# LPC112x register map
File version: 0.3
CPU: CM0 r0p0, little endian, no MPU, no FPU, 2 interrupt priority bits
Registers are 32-bit, read-write, reset 0x0 unless marked. A register's access mark holds for its fields unless they carry their own. Offsets are from the block's base; [hi:lo] are bit positions; 'fields as' and 'values as' point back to an identical list.

## IOCON — I/O configuration (IOCON)
Base 0x40044000
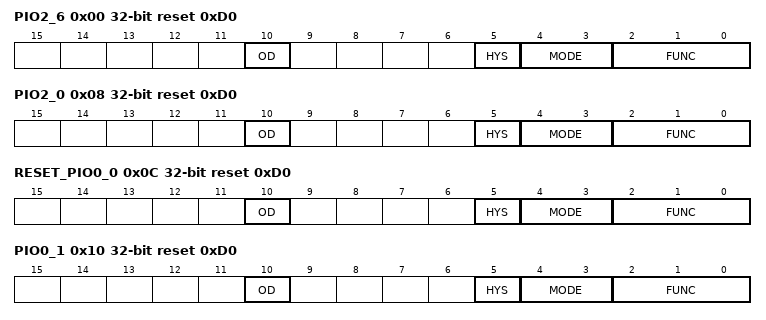
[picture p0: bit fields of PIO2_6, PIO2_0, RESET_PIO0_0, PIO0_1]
0x00 PIO2_6 reset 0xD0 — I/O configuration for pin PIO2_6/ CT32B0_MAT1
  [10] OD — Selects pseudo open-drain mode.
    0=STANDARD_GPIO_OUTPUT; 1=OPEN_DRAIN_OUTPUT
  [5] HYS — Hysteresis.
    0=DISABLE; 1=ENABLE
  [4:3] MODE — Selects function mode (on-chip pull-up/pull-down resistor control).
    0=INACTIVE_NO_PULL_DO (Inactive (no pull-down/pull-up resistor enabled).); 1=PULL_DOWN_RESISTOR_E (Pull-down resistor enabled.); 2=PULL_UP_RESISTOR_ENA (Pull-up resistor enabled.); 3=REPEATER_MODE
  [2:0] FUNC — Selects pin function. All other values are reserved.
    0=PIO2_6; 1=CT32B0_MAT1
0x08 PIO2_0 reset 0xD0 — I/O configuration for pin PIO2_0/U0_DTR/SSP1_SSEL/ ADC_PIN_TRIG4
  [10] OD — Selects pseudo open-drain mode.
    0=STANDARD_GPIO_OUTPUT; 1=OPEN_DRAIN_OUTPUT
  [5] HYS — Hysteresis.
    0=DISABLE; 1=ENABLE
  [4:3] MODE — Selects function mode (on-chip pull-up/pull-down resistor control).
    values as PIO2_6.MODE
  [2:0] FUNC — Selects pin function. All other values are reserved.
    0=PIO2_0; 1=U0_DTR; 2=SSP1_SSEL; 3=ADC_PIN_TRIG4
0x0C RESET_PIO0_0 reset 0xD0 — I/O configuration for pin RESET/PIO0_0
  [10] OD — Selects pseudo open-drain mode.
    0=STANDARD_GPIO_OUTPUT; 1=OPEN_DRAIN_OUTPUT
  [5] HYS — Hysteresis.
    0=DISABLE; 1=ENABLE
  [4:3] MODE — Selects function mode (on-chip pull-up/pull-down resistor control).
    values as PIO2_6.MODE
  [2:0] FUNC — Selects pin function. All other values are reserved.
    0=RESET; 1=PIO0_0
0x10 PIO0_1 reset 0xD0 — I/O configuration for pin PIO0_1/CLKOUT/CT32B0_MAT2
  [10] OD — Selects pseudo open-drain mode.
    0=STANDARD_GPIO_OUTPUT; 1=OPEN_DRAIN_OUTPUT
  [5] HYS — Hysteresis.
    0=DISABLE; 1=ENABLE
  [4:3] MODE — Selects function mode (on-chip pull-up/pull-down resistor control).
    values as PIO2_6.MODE
  [2:0] FUNC — Selects pin function. All other values are reserved.
    0=PIO0_1; 1=CLKOUT; 2=CT32B0_MAT2
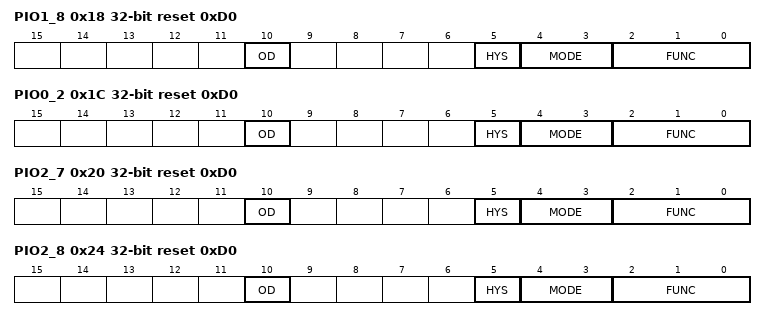
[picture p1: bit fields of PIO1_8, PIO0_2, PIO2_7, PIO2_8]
0x18 PIO1_8 reset 0xD0 — I/O configuration for pin PIO1_8/CT16B1_CAP0/R/U2_TXD
  [10] OD — Selects pseudo open-drain mode.
    0=STANDARD_GPIO_OUTPUT; 1=OPEN_DRAIN_OUTPUT
  [5] HYS — Hysteresis.
    0=DISABLE; 1=ENABLE
  [4:3] MODE — Selects function mode (on-chip pull-up/pull-down resistor control).
    values as PIO2_6.MODE
  [2:0] FUNC — Selects pin function. All other values are reserved.
    0=PIO1_8; 1=CT16B1_CAP0; 3=U2_TXD
0x1C PIO0_2 reset 0xD0 — I/O configuration for pin PIO0_2/SSP0_SSEL/CT16B0_CAP0/ ADC_PIN_TRIG0
  [10] OD — Selects pseudo open-drain mode.
    0=STANDARD_GPIO_OUTPUT; 1=OPEN_DRAIN_OUTPUT
  [5] HYS — Hysteresis.
    0=DISABLE; 1=ENABLE
  [4:3] MODE — Selects function mode (on-chip pull-up/pull-down resistor control).
    values as PIO2_6.MODE
  [2:0] FUNC — Selects pin function. All other values are reserved.
    0=PIO0_2; 1=SSP0_SSEL; 2=CT16B0_CAP0; 3=ADC_PIN_TRIG0
0x20 PIO2_7 reset 0xD0 — I/O configuration for pin PIO2_7/ CT32B0_MAT2/U0_RXD
  [10] OD — Selects pseudo open-drain mode.
    0=STANDARD_GPIO_OUTPUT; 1=OPEN_DRAIN_OUTPUT
  [5] HYS — Hysteresis.
    0=DISABLE; 1=ENABLE
  [4:3] MODE — Selects function mode (on-chip pull-up/pull-down resistor control).
    values as PIO2_6.MODE
  [2:0] FUNC — Selects pin function. All other values are reserved.
    0=PIO2_7; 1=CT32B0_MAT2; 2=U0_RXD
0x24 PIO2_8 reset 0xD0 — I/O configuration for pin PIO2_8/ CT32B0_MAT3/U0_TXD
  [10] OD — Selects pseudo open-drain mode.
    0=STANDARD_GPIO_OUTPUT; 1=OPEN_DRAIN_OUTPUT
  [5] HYS — Hysteresis.
    0=DISABLE; 1=ENABLE
  [4:3] MODE — Selects function mode (on-chip pull-up/pull-down resistor control).
    values as PIO2_6.MODE
  [2:0] FUNC — Selects pin function. All other values are reserved.
    0=PIO2_8; 1=CT32B0_MAT3; 2=U0_TXD
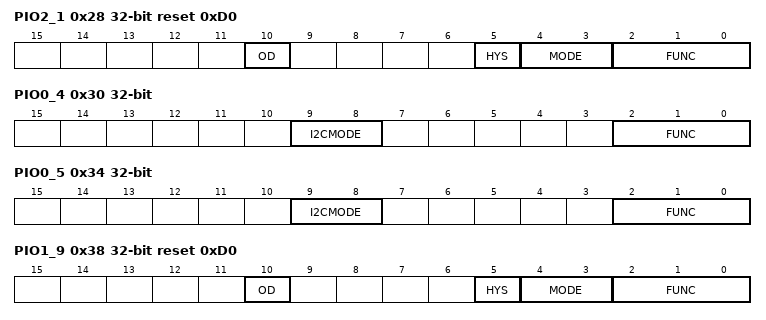
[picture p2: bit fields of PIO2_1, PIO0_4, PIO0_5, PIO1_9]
0x28 PIO2_1 reset 0xD0 — I/O configuration for pin PIO2_1/U0_DSR/SSP1_SCK
  [10] OD — Selects pseudo open-drain mode.
    0=STANDARD_GPIO_OUTPUT; 1=OPEN_DRAIN_OUTPUT
  [5] HYS — Hysteresis.
    0=DISABLE; 1=ENABLE
  [4:3] MODE — Selects function mode (on-chip pull-up/pull-down resistor control).
    values as PIO2_6.MODE
  [2:0] FUNC — Selects pin function. All other values are reserved.
    0=PIO2_1; 1=U0_DSR; 2=SSP1_SCK
0x30 PIO0_4 — I/O configuration for pin PIO0_4/I2C0_SCL
  [9:8] I2CMODE — Selects I2C mode. Select Standard mode (I2CMODE = 00, default) or Standard I/O functionality (I2CMODE = 01) if the pin function is GPIO (FUNC = 000).
    0=STANDARD_FAST (Standard mode/ Fast-mode I2C.); 1=STANDARDIO (Standard I/O functionality); 2=FAST_MODE_PLUS_I2C
  [2:0] FUNC — Selects pin function. All other values are reserved.
    0=PIO0_4_OPEN_DRAIN_P (PIO0_4 (open-drain pin).); 1=I2C0_SCL_OPEN_DRAIN (I2C0_SCL (open-drain pin).)
0x34 PIO0_5 — I/O configuration for pin PIO0_5/I2C0_SDA
  [9:8] I2CMODE — Selects I2C mode. Select Standard mode (I2CMODE = 00, default) or Standard I/O functionality (I2CMODE = 01) if the pin function is GPIO (FUNC = 000).
    values as PIO0_4.I2CMODE
  [2:0] FUNC — Selects pin function. All other values are reserved.
    0=PIO0_5_OPEN_DRAIN_P (PIO0_5 (open-drain pin).); 1=I2C0_SDA_OPEN_DRAIN (I2C0_SDA (open-drain pin).)
0x38 PIO1_9 reset 0xD0 — I/O configuration for pin PIO1_9/CT16B1_MAT0/SSP1_ MOSI
  [10] OD — Selects pseudo open-drain mode.
    0=STANDARD_GPIO_OUTPUT; 1=OPEN_DRAIN_OUTPUT
  [5] HYS — Hysteresis.
    0=DISABLE; 1=ENABLE
  [4:3] MODE — Selects function mode (on-chip pull-up/pull-down resistor control).
    values as PIO2_6.MODE
  [2:0] FUNC — Selects pin function. All other values are reserved.
    0=PIO1_9; 1=CT16B1_MAT0; 2=SSP1_MOSI
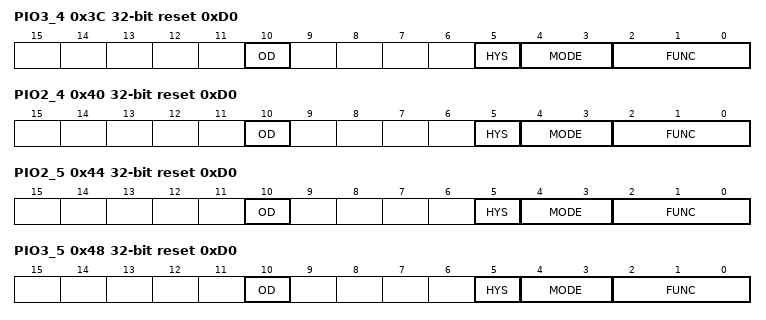
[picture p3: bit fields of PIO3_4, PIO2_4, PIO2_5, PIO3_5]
0x3C PIO3_4 reset 0xD0 — I/O configuration for pin PIO3_4/ CT16B0_CAP1/U0_RXD
  [10] OD — Selects pseudo open-drain mode.
    0=STANDARD_GPIO_OUTPUT; 1=OPEN_DRAIN_OUTPUT
  [5] HYS — Hysteresis.
    0=DISABLE; 1=ENABLE
  [4:3] MODE — Selects function mode (on-chip pull-up/pull-down resistor control).
    values as PIO2_6.MODE
  [2:0] FUNC — Selects pin function. All other values are reserved.
    0=PIO3_4; 1=CT16B0_CAP1; 2=U0_RXD
0x40 PIO2_4 reset 0xD0 — I/O configuration for pin PIO2_4/ CT16B1_MAT1/ SSP1_SSEL
  [10] OD — Selects pseudo open-drain mode.
    0=STANDARD_GPIO_OUTPUT; 1=OPEN_DRAIN_OUTPUT
  [5] HYS — Hysteresis.
    0=DISABLE; 1=ENABLE
  [4:3] MODE — Selects function mode (on-chip pull-up/pull-down resistor control).
    values as PIO2_6.MODE
  [2:0] FUNC — Selects pin function. All other values are reserved.
    0=PIO2_4; 1=CT16B1_MAT1; 2=SSP1_SSEL
0x44 PIO2_5 reset 0xD0 — I/O configuration for pin PIO2_5/ CT32B0_MAT0
  [10] OD — Selects pseudo open-drain mode.
    0=STANDARD_GPIO_OUTPUT; 1=OPEN_DRAIN_OUTPUT
  [5] HYS — Hysteresis.
    0=DISABLE; 1=ENABLE
  [4:3] MODE — Selects function mode (on-chip pull-up/pull-down resistor control).
    values as PIO2_6.MODE
  [2:0] FUNC — Selects pin function. All other values are reserved.
    0=PIO2_5; 1=CT32B0_MAT0
0x48 PIO3_5 reset 0xD0 — I/O configuration for pin PIO3_5/ CT16B1_CAP1/U0_TXD
  [10] OD — Selects pseudo open-drain mode.
    0=STANDARD_GPIO_OUTPUT; 1=OPEN_DRAIN_OUTPUT
  [5] HYS — Hysteresis.
    0=DISABLE; 1=ENABLE
  [4:3] MODE — Selects function mode (on-chip pull-up/pull-down resistor control).
    values as PIO2_6.MODE
  [2:0] FUNC — Selects pin function. All other values are reserved.
    0=PIO3_5; 1=CT16B1_CAP1; 2=U0_TXD
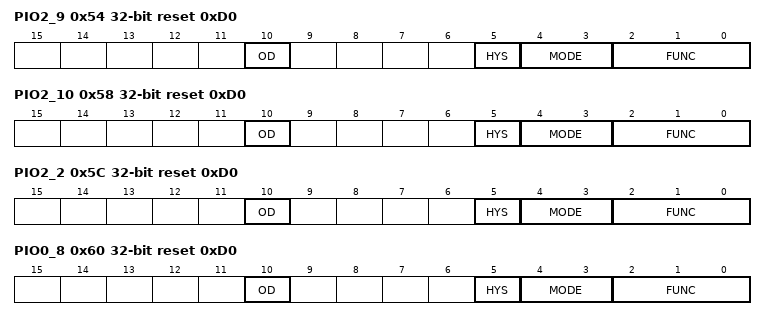
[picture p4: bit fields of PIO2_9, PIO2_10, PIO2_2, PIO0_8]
0x54 PIO2_9 reset 0xD0 — I/O configuration for pin PIO2_9/ CT32B0_CAP0
  [10] OD — Selects pseudo open-drain mode.
    0=STANDARD_GPIO_OUTPUT; 1=OPEN_DRAIN_OUTPUT
  [5] HYS — Hysteresis.
    0=DISABLE; 1=ENABLE
  [4:3] MODE — Selects function mode (on-chip pull-up/pull-down resistor control).
    values as PIO2_6.MODE
  [2:0] FUNC — Selects pin function. All other values are reserved.
    0=PIO2_9; 1=CT32B0_CAP0
0x58 PIO2_10 reset 0xD0 — I/O configuration for pin PIO2_10
  [10] OD — Selects pseudo open-drain mode.
    0=STANDARD_GPIO_OUTPUT; 1=OPEN_DRAIN_OUTPUT
  [5] HYS — Hysteresis.
    0=DISABLE; 1=ENABLE
  [4:3] MODE — Selects function mode (on-chip pull-up/pull-down resistor control).
    values as PIO2_6.MODE
  [2:0] FUNC — Selects pin function. All other values are reserved.
    0=PIO2_10
0x5C PIO2_2 reset 0xD0 — I/O configuration for pin PIO2_2/U0_DCD/SSP1_MISO
  [10] OD — Selects pseudo open-drain mode.
    0=STANDARD_GPIO_OUTPUT; 1=OPEN_DRAIN_OUTPUT
  [5] HYS — Hysteresis.
    0=DISABLE; 1=ENABLE
  [4:3] MODE — Selects function mode (on-chip pull-up/pull-down resistor control).
    values as PIO2_6.MODE
  [2:0] FUNC — Selects pin function. All other values are reserved.
    0=PIO2_2; 1=U0_DCD; 2=SSP1_MISO
0x60 PIO0_8 reset 0xD0 — I/O configuration for pin PIO0_8/SSP0_MISO/CT16B0_MAT0/R/ADC_PIN_TRIG2
  [10] OD — Selects pseudo open-drain mode.
    0=STANDARD_GPIO_OUTPUT; 1=OPEN_DRAIN_OUTPUT
  [5] HYS — Hysteresis.
    0=DISABLE; 1=ENABLE
  [4:3] MODE — Selects function mode (on-chip pull-up/pull-down resistor control).
    values as PIO2_6.MODE
  [2:0] FUNC — Selects pin function. All other values are reserved.
    0=PIO0_8; 1=SSP0_MISO; 2=CT16B0_MAT0; 4=ADC_PIN_TRIG2
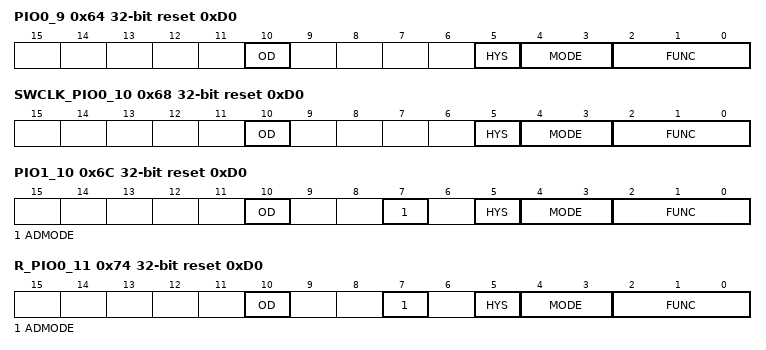
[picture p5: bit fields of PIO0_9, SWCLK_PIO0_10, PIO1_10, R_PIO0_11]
0x64 PIO0_9 reset 0xD0 — I/O configuration for pin PIO0_9SSP0_MOSI/CT16B0_MAT1/R/ADC_PIN_TRIG3
  [10] OD — Selects pseudo open-drain mode.
    0=STANDARD_GPIO_OUTPUT; 1=OPEN_DRAIN_OUTPUT
  [5] HYS — Hysteresis.
    0=DISABLE; 1=ENABLE
  [4:3] MODE — Selects function mode (on-chip pull-up/pull-down resistor control).
    values as PIO2_6.MODE
  [2:0] FUNC — Selects pin function. All other values are reserved.
    0=PIO0_9; 1=SSP0_MOSI; 2=CT16B0_MAT1; 4=ADC_PIN_TRIG3
0x68 SWCLK_PIO0_10 reset 0xD0 — I/O configuration for pin SWCLK/PIO0_10/ SSP0_SCK/CT16B0_MAT2
  [10] OD — Selects pseudo open-drain mode.
    0=STANDARD_GPIO_OUTPUT; 1=OPEN_DRAIN_OUTPUT
  [5] HYS — Hysteresis.
    0=DISABLE; 1=ENABLE
  [4:3] MODE — Selects function mode (on-chip pull-up/pull-down resistor control).
    values as PIO2_6.MODE
  [2:0] FUNC — Selects pin function. All other values are reserved.
    0=SWCLK; 1=PIO0_10; 2=SSP0_SCK_ONLY_IF_PI (SSP0_SCK (only if pin SWCLK/PIO0_10/SSP0_SCK/CT16B0_MAT2 selected in the SCK0_LOC register).); 3=CT16B0_MAT2
0x6C PIO1_10 reset 0xD0 — I/O configuration for pin PIO1_10/ADC_8/CT16B1_MAT1/ SSP1_MISO
  [10] OD — Selects pseudo open-drain mode.
    0=STANDARD_GPIO_OUTPUT; 1=OPEN_DRAIN_OUTPUT
  [7] ADMODE — Selects Analog/Digital mode
    0=ANALOG_INPUT_MODE; 1=DIGITAL_FUNCTIONAL_M (Digital functional mode)
  [5] HYS — Hysteresis.
    0=DISABLE; 1=ENABLE
  [4:3] MODE — Selects function mode (on-chip pull-up/pull-down resistor control).
    values as PIO2_6.MODE
  [2:0] FUNC — Selects pin function. All other values are reserved.
    0=PIO1_10; 1=ADC_8; 2=CT16B1_MAT1; 3=SSP1_MISO
0x74 R_PIO0_11 reset 0xD0 — I/O configuration for pin R/PIO0_11/ADC_7/CT32B0_MAT3
  [10] OD — Selects pseudo open-drain mode.
    0=STANDARD_GPIO_OUTPUT; 1=OPEN_DRAIN_OUTPUT
  [7] ADMODE — Selects Analog/Digital mode
    values as PIO1_10.ADMODE
  [5] HYS — Hysteresis.
    0=DISABLE; 1=ENABLE
  [4:3] MODE — Selects function mode (on-chip pull-up/pull-down resistor control).
    values as PIO2_6.MODE
  [2:0] FUNC — Selects pin function. All other values are reserved.
    0=R (R. This function is reserved. Select one of the alternate functions below.); 1=PIO0_11; 2=ADC_7; 3=CT32B0_MAT3
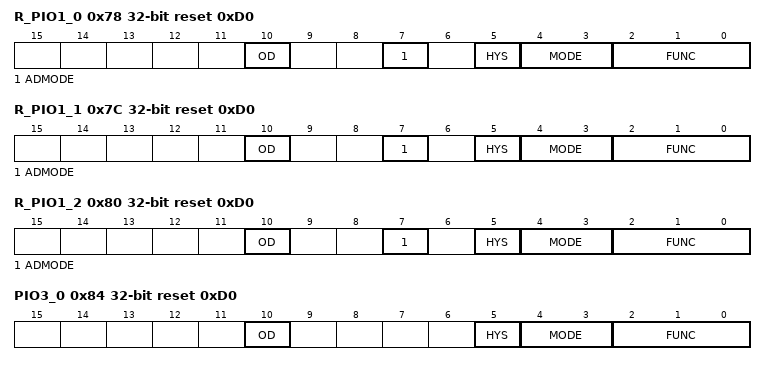
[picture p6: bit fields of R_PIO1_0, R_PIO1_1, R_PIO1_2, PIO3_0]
0x78 R_PIO1_0 reset 0xD0 — I/O configuration for pin R/PIO1_0/ADC_6/CT32B1_CAP0
  [10] OD — Selects pseudo open-drain mode.
    0=STANDARD_GPIO_OUTPUT; 1=OPEN_DRAIN_OUTPUT
  [7] ADMODE — Selects Analog/Digital mode
    values as PIO1_10.ADMODE
  [5] HYS — Hysteresis.
    0=DISABLE; 1=ENABLE
  [4:3] MODE — Selects function mode (on-chip pull-up/pull-down resistor control).
    values as PIO2_6.MODE
  [2:0] FUNC — Selects pin function. All other values are reserved.
    0=R (R. This function is reserved. Select one of the alternate functions below.); 1=PIO1_0; 2=ADC_6; 3=CT32B1_CAP0
0x7C R_PIO1_1 reset 0xD0 — I/O configuration for pin R/PIO1_1/ADC_5/CT32B1_MAT0
  [10] OD — Selects pseudo open-drain mode.
    0=STANDARD_GPIO_OUTPUT; 1=OPEN_DRAIN_OUTPUT
  [7] ADMODE — Selects Analog/Digital mode
    values as PIO1_10.ADMODE
  [5] HYS — Hysteresis.
    0=DISABLE; 1=ENABLE
  [4:3] MODE — Selects function mode (on-chip pull-up/pull-down resistor control).
    values as PIO2_6.MODE
  [2:0] FUNC — Selects pin function. All other values are reserved.
    0=R (R. This function is reserved. Select one of the alternate functions below.); 1=PIO1_1; 2=ADC_5; 3=CT32B1_MAT0
0x80 R_PIO1_2 reset 0xD0 — I/O configuration for pin R/PIO1_2/ADC_4/CT32B1_MAT1
  [10] OD — Selects pseudo open-drain mode.
    0=STANDARD_GPIO_OUTPUT; 1=OPEN_DRAIN_OUTPUT
  [7] ADMODE — Selects Analog/Digital mode
    values as PIO1_10.ADMODE
  [5] HYS — Hysteresis.
    0=DISABLE; 1=ENABLE
  [4:3] MODE — Selects function mode (on-chip pull-up/pull-down resistor control).
    values as PIO2_6.MODE
  [2:0] FUNC — Selects pin function. All other values are reserved.
    0=R (R. This function is reserved. Select one of the alternate functions below.); 1=PIO1_2; 2=ADC_4; 3=CT32B1_MAT1
0x84 PIO3_0 reset 0xD0 — I/O configuration for pin PIO3_0/U0_DTR/CT16B0_MAT0/ U0_TXD
  [10] OD — Selects pseudo open-drain mode.
    0=STANDARD_GPIO_OUTPUT; 1=OPEN_DRAIN_OUTPUT
  [5] HYS — Hysteresis.
    0=DISABLE; 1=ENABLE
  [4:3] MODE — Selects function mode (on-chip pull-up/pull-down resistor control).
    values as PIO2_6.MODE
  [2:0] FUNC — Selects pin function. All other values are reserved.
    0=PIO3_0; 1=U0_DTR; 2=CT16B0_MAT0; 3=U0_TXD
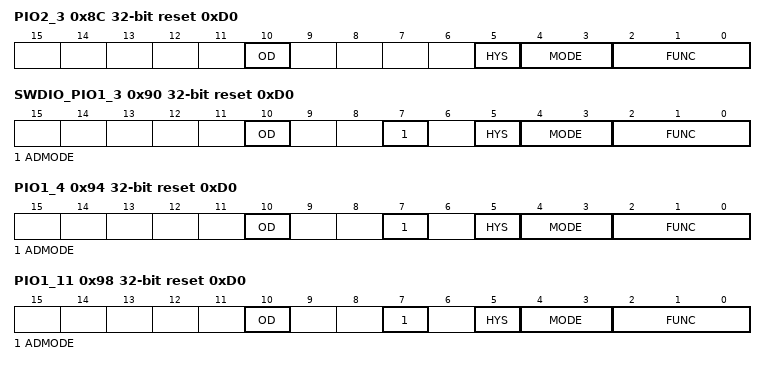
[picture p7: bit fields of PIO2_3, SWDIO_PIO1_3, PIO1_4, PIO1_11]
0x8C PIO2_3 reset 0xD0 — I/O configuration for pin PIO2_3/U0_RI/SSP1_MOSI
  [10] OD — Selects pseudo open-drain mode.
    0=STANDARD_GPIO_OUTPUT; 1=OPEN_DRAIN_OUTPUT
  [5] HYS — Hysteresis.
    0=DISABLE; 1=ENABLE
  [4:3] MODE — Selects function mode (on-chip pull-up/pull-down resistor control).
    values as PIO2_6.MODE
  [2:0] FUNC — Selects pin function. All other values are reserved.
    0=PIO2_3; 1=U0_RI; 2=SSP1_MOSI
0x90 SWDIO_PIO1_3 reset 0xD0 — I/O configuration for pin SWDIO/PIO1_3/ADC_3/CT32B1_MAT2
  [10] OD — Selects pseudo open-drain mode.
    0=STANDARD_GPIO_OUTPUT; 1=OPEN_DRAIN_OUTPUT
  [7] ADMODE — Selects Analog/Digital mode
    values as PIO1_10.ADMODE
  [5] HYS — Hysteresis.
    0=DISABLE; 1=ENABLE
  [4:3] MODE — Selects function mode (on-chip pull-up/pull-down resistor control).
    values as PIO2_6.MODE
  [2:0] FUNC — Selects pin function. All other values are reserved.
    0=SWDIO; 1=PIO1_3; 2=ADC_3; 3=CT32B1_MAT2
0x94 PIO1_4 reset 0xD0 — I/O configuration for pin PIO1_4/ADC_2/CT32B1_MAT3
  [10] OD — Selects pseudo open-drain mode.
    0=STANDARD_GPIO_OUTPUT; 1=OPEN_DRAIN_OUTPUT
  [7] ADMODE — Selects Analog/Digital mode
    values as PIO1_10.ADMODE
  [5] HYS — Hysteresis.
    0=DISABLE; 1=ENABLE
  [4:3] MODE — Selects function mode (on-chip pull-up/pull-down resistor control).
    values as PIO2_6.MODE
  [2:0] FUNC — Selects pin function. This pin functions as WAKEUP pin if the part is in Deep power-down mode regardless of the value of FUNC. All other values are reserved.
    0=PIO1_4; 1=ADC_2; 2=CT32B1_MAT3
0x98 PIO1_11 reset 0xD0 — I/O configuration for pin PIO1_11/ADC_1/CT32B1_CAP1
  [10] OD — Selects pseudo open-drain mode.
    0=STANDARD_GPIO_OUTPUT; 1=OPEN_DRAIN_OUTPUT
  [7] ADMODE — Selects Analog/Digital mode
    values as PIO1_10.ADMODE
  [5] HYS — Hysteresis.
    0=DISABLE; 1=ENABLE
  [4:3] MODE — Selects function mode (on-chip pull-up/pull-down resistor control).
    values as PIO2_6.MODE
  [2:0] FUNC — Selects pin function. All other values are reserved.
    0=PIO1_11; 1=ADC_1; 2=CT32B1_CAP1
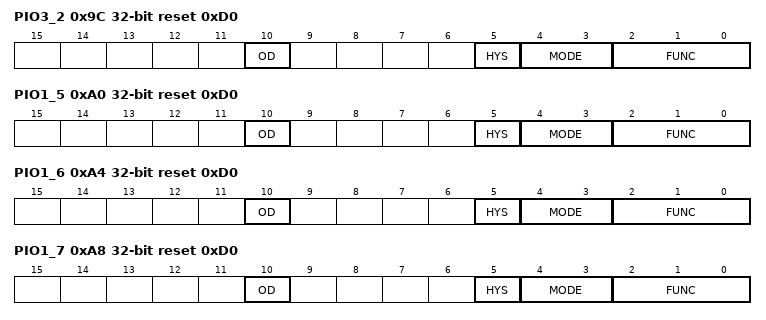
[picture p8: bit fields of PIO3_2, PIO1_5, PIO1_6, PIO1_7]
0x9C PIO3_2 reset 0xD0 — I/O configuration for pin PIO3_2/U0_DCD/ CT16B0_MAT2/SSP1_SCK
  [10] OD — Selects pseudo open-drain mode.
    0=STANDARD_GPIO_OUTPUT; 1=OPEN_DRAIN_OUTPUT
  [5] HYS — Hysteresis.
    0=DISABLE; 1=ENABLE
  [4:3] MODE — Selects function mode (on-chip pull-up/pull-down resistor control).
    values as PIO2_6.MODE
  [2:0] FUNC — Selects pin function. All other values are reserved.
    0=PIO3_2; 1=U0_DCD; 2=CT16B0_MAT2; 3=SSP1_SCK
0xA0 PIO1_5 reset 0xD0 — I/O configuration for pin PIO1_5/U0_RTS/CT32B0_CAP0
  [10] OD — Selects pseudo open-drain mode.
    0=STANDARD_GPIO_OUTPUT; 1=OPEN_DRAIN_OUTPUT
  [5] HYS — Hysteresis.
    0=DISABLE; 1=ENABLE
  [4:3] MODE — Selects function mode (on-chip pull-up/pull-down resistor control).
    values as PIO2_6.MODE
  [2:0] FUNC — Selects pin function. All other values are reserved.
    0=PIO1_5; 1=U0_RTS; 2=CT32B0_CAP0
0xA4 PIO1_6 reset 0xD0 — I/O configuration for pin PIO1_6/U0_RXD/CT32B0_MAT0
  [10] OD — Selects pseudo open-drain mode.
    0=STANDARD_GPIO_OUTPUT; 1=OPEN_DRAIN_OUTPUT
  [5] HYS — Hysteresis.
    0=DISABLE; 1=ENABLE
  [4:3] MODE — Selects function mode (on-chip pull-up/pull-down resistor control).
    values as PIO2_6.MODE
  [2:0] FUNC — Selects pin function. All other values are reserved.
    0=PIO1_6; 1=U0_RXD; 2=CT32B0_MAT0
0xA8 PIO1_7 reset 0xD0 — I/O configuration for pin PIO1_7/U0_TXD/CT32B0_MAT1
  [10] OD — Selects pseudo open-drain mode.
    0=STANDARD_GPIO_OUTPUT; 1=OPEN_DRAIN_OUTPUT
  [5] HYS — Hysteresis.
    0=DISABLE; 1=ENABLE
  [4:3] MODE — Selects function mode (on-chip pull-up/pull-down resistor control).
    values as PIO2_6.MODE
  [2:0] FUNC — Selects pin function. All other values are reserved.
    0=PIO1_7; 1=U0_TXD; 2=CT32B0_MAT1
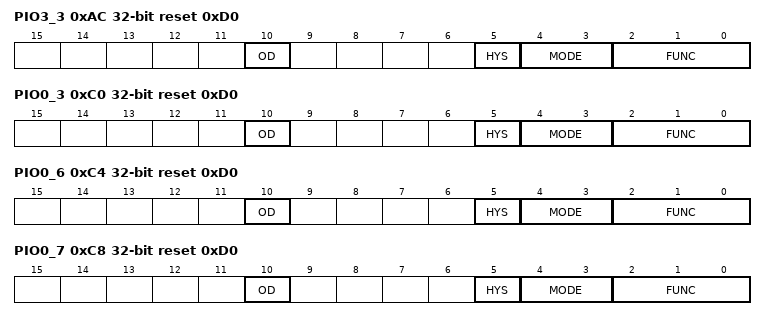
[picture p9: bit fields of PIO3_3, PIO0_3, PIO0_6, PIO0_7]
0xAC PIO3_3 reset 0xD0 — I/O configuration for pin PIO3_3/U0_RI/ CT16B0_CAP0
  [10] OD — Selects pseudo open-drain mode.
    0=STANDARD_GPIO_OUTPUT; 1=OPEN_DRAIN_OUTPUT
  [5] HYS — Hysteresis.
    0=DISABLE; 1=ENABLE
  [4:3] MODE — Selects function mode (on-chip pull-up/pull-down resistor control).
    values as PIO2_6.MODE
  [2:0] FUNC — Selects pin function. All other values are reserved.
    0=PIO3_3; 1=U0_RI; 2=CT16B0_CAP0
0xB0 SCK0_LOC — SCK0 pin location select register
  [1:0] SCKLOC — Selects pin location for SSP0_SCK function.
    0=PIO0_10 (PIO0_10. Selects SCK0 function in pin location SWCLK/PIO0_10.); 2=PIO0_6 (PIO0_6. Selects SSP0_SCK function in pin location PIO0_6.)
0xB4 DSR_LOC — DSR pin location select register
  [1:0] DSRLOC — Selects pin location for U0_DSR function.
    0=PIO2_1 (PIO2_1. Selects U0_DSR function in pin location PIO2_1)
0xB8 DCD_LOC — DCD pin location select register
  [1:0] DCDLOC — Selects pin location for U0_DCD function.
    0=PIO2_2 (PIO2_2. Selects U0_DCD function in pin location PIO2_2.); 1=PIO3_2 (PIO3_2. Selects U0_DCD function in pin location PIO3_2.)
0xBC RI_LOC — RI pin location select register
  [1:0] RILOC — Selects pin location for U0_RI function.
    0=PIO2_3 (PIO2_3. Selects UO_RI function in pin location PIO2_3.); 1=PIO3_3 (PIO3_3. Selects U0_RI function in pin location PIO3_3.)
0xC0 PIO0_3 reset 0xD0 — I/O configuration for pin PIO0_3/R/R/U2_RXD
  [10] OD — Selects pseudo open-drain mode.
    0=STANDARD_GPIO_OUTPUT; 1=OPEN_DRAIN_OUTPUT
  [5] HYS — Hysteresis.
    0=DISABLE; 1=ENABLE
  [4:3] MODE — Selects function mode (on-chip pull-up/pull-down resistor control).
    values as PIO2_6.MODE
  [2:0] FUNC — Selects pin function. All other values are reserved.
    0=PIO0_3; 3=U2_RXD
0xC4 PIO0_6 reset 0xD0 — I/O configuration for pin PIO0_6/SSP0_SCK/U1_TXD
  [10] OD — Selects pseudo open-drain mode.
    0=STANDARD_GPIO_OUTPUT; 1=OPEN_DRAIN_OUTPUT
  [5] HYS — Hysteresis.
    0=DISABLE; 1=ENABLE
  [4:3] MODE — Selects function mode (on-chip pull-up/pull-down resistor control).
    values as PIO2_6.MODE
  [2:0] FUNC — Selects pin function. All other values are reserved.
    0=PIO0_6; 2=SSP0_SCK_ONLY_IF_PI (SSP0_SCK (only if pin PIO0_6/SSP0_SCK selected in the SCK0_LOC register).); 3=U1_TXD
0xC8 PIO0_7 reset 0xD0 — I/O configuration for pin PIO0_7/U0_CTS/ADC_PIN_TRIG1/U1_RXD
  [10] OD — Selects pseudo open-drain mode.
    0=STANDARD_GPIO_OUTPUT; 1=OPEN_DRAIN_OUTPUT
  [5] HYS — Hysteresis.
    0=DISABLE; 1=ENABLE
  [4:3] MODE — Selects function mode (on-chip pull-up/pull-down resistor control).
    values as PIO2_6.MODE
  [2:0] FUNC — Selects pin function. All other values are reserved.
    0=PIO0_7; 1=U0_CTS; 2=ADC_PIN_TRIG1; 3=U1_RXD
0xCC SSEL1_LOC — SSEL1 pin location select register
  [1:0] SSEL1LOC — Selects pin location for SSP1_SSEL function.
    0=PIO2_0 (PIO2_0. Selects SSP1_SSEL function in pin location PIO2_0.); 1=PIO2_4 (PIO2_4. Selects SSP1_SSEL function in pin location PIO2_4.)
0xD0 CT16B0_CAP0_LOC — CT16B0_CAP0 pin location select register
  [1:0] CT16B0_CAP0LOC — Selects pin location for CT16B0_CAP0 function.
    0=PIO0_2 (PIO0_2. Selects CT16B0_CAP0 function in pin location PIO0_2.); 1=PIO3_3 (PIO3_3. Selects CT16B0_CAP0 function in pin location PIO3_3.)
0xD4 SCK1_LOC — SCK1 pin location select register
  [1:0] SCK1LOC — Selects pin location for SSP1_SCK function.
    0=PIO2_1 (PIO2_1. Selects SSP1_SCK function in pin location PIO2_1.); 1=PIO3_2 (PIO3_2. Selects SSP1_SCK function in pin location PIO3_2.)
0xD8 MISO1_LOC — MISO1 pin location select register
  [1:0] MISO1LOC — Selects pin location for the SSP1_MISO function.
    0=PIO2_2 (PIO2_2. Selects SSP1_MISO function in pin location PIO2_2.); 1=PIO1_10 (PIO1_10. Selects SSP1_MISO function in pin location PIO1_10.)
0xDC MOSI1_LOC — MOSI1 pin location select register
  [1:0] MOSI1LOC — Selects pin location for the SSP1_MOSI function.
    0=PIO2_3 (PIO2_3. Selects SSP1_MOSI1 function in pin location PIO2_3.); 1=PIO1_9 (PIO1_9. Selects SSP1_MOSI function in pin location PIO1_9.)
0xE0 CT32B0_CAP0_LOC — CT32B0_CAP0 pin location select register
  [1:0] CT32B0_CAP0LOC — Selects pin location for the CT32B0_CAP0 function.
    0=PIO1_5 (PIO1_5. Selects CT32B0_CAP0 function in pin location PIO1_5.); 1=PIO2_9 (PIO2_9. Selects CT32B0_CAP0 function in pin location PIO2_9.)
0xE4 RXD_LOC — RXD pin location select register
  [1:0] RXDLOC — Selects pin location for the U0_RXD function.
    0=PIO1_6 (PIO1_6. Selects U0_RXD function in pin location PIO1_6.); 1=PIO2_7 (PIO2_7. Selects RXD function in pin location PIO2_7.); 3=PIO3_4 (PIO3_4. Selects RXD function in pin location PIO3_4.)
